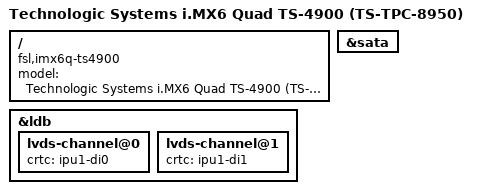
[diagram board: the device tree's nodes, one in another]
/*
 * Copyright 2011 Freescale Semiconductor, Inc.
 * Copyright 2011 Linaro Ltd.
 *
 * The code contained herein is licensed under the GNU General Public
 * License. You may obtain a copy of the GNU General Public License
 * Version 2 or later at the following locations:
 *
 * http://www.opensource.org/licenses/gpl-license.html
 * http://www.gnu.org/copyleft/gpl.html
 */

/dts-v1/;
#include "imx6q.dtsi"
#include "imx6qdl-ts4900-14.dtsi"

/ {
	model = "Technologic Systems i.MX6 Quad TS-4900 (TS-TPC-8950)";
	compatible = "fsl,imx6q-ts4900", "fsl,imx6q";
};

&ldb {
	lvds-channel@0 {
		crtc = "ipu1-di0";
	};

	lvds-channel@1 {
		crtc = "ipu1-di1";
	};
};


&sata {
        status = "okay";
};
